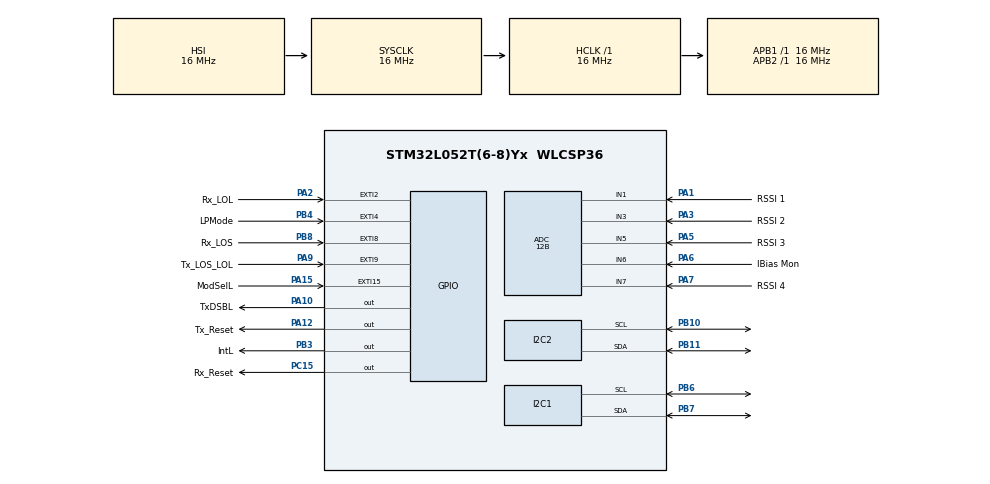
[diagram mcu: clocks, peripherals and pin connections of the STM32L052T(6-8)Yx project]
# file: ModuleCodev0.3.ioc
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ADC.ClockPrescaler=ADC_CLOCK_SYNC_PCLK_DIV1
ADC.ContinuousConvMode=DISABLE
ADC.DMAContinuousRequests=DISABLE
ADC.DataAlign=ADC_DATAALIGN_RIGHT
ADC.DiscontinuousConvMode=DISABLE
ADC.EOCSelection=ADC_EOC_SINGLE_CONV
ADC.EnableAnalogWatchDog=false
ADC.ExternalTrigConv=ADC_SOFTWARE_START
ADC.ExternalTrigConvEdge=ADC_EXTERNALTRIGCONVEDGE_NONE
ADC.LowPowerAutoPowerOff=DISABLE
ADC.LowPowerAutoWait=DISABLE
ADC.LowPowerFrequencyMode=DISABLE
ADC.Overrun=ADC_OVR_DATA_PRESERVED
ADC.OversamplingMode=DISABLE
ADC.Resolution=ADC_RESOLUTION_12B
ADC.SamplingTime=ADC_SAMPLETIME_1CYCLE_5
ADC.ScanConvMode=ADC_SCAN_DIRECTION_FORWARD
I2C1.OwnAddress=80
I2C1.Timing=0x00303D5B
I2C2.Timing=0x00303D5B
Mcu.Family=STM32L0
Mcu.Name=STM32L052T(6-8)Yx
Mcu.Package=WLCSP36
NVIC.ADC1_COMP_IRQn=true\:1\:0\:true\:false\:true
NVIC.EXTI2_3_IRQn=true\:2\:0\:true\:false\:true
NVIC.EXTI4_15_IRQn=true\:2\:0\:true\:false\:true
NVIC.I2C1_IRQn=true\:3\:0\:true\:false\:true
PA1.GPIO_Label=RSSI 1
PA1.Mode=IN1
PA1.Signal=ADC_IN1
PA10.GPIO_Label=TxDSBL
PA10.GPIO_ModeDefaultOutputPP=GPIO_MODE_OUTPUT_OD
PA10.GPIO_PuPd=GPIO_PULLUP
PA10.PinState=GPIO_PIN_RESET
PA10.Signal=GPIO_Output
PA12.GPIO_Label=Tx_Reset
PA12.GPIO_ModeDefaultOutputPP=GPIO_MODE_OUTPUT_OD
PA12.GPIO_PuPd=GPIO_PULLUP
PA12.PinState=GPIO_PIN_RESET
PA12.Signal=GPIO_Output
PA13.Mode=Serial_Wire
PA13.Signal=SYS_SWDIO
PA14.Mode=Serial_Wire
PA14.Signal=SYS_SWCLK
PA15.GPIO_Label=ModSelL
PA15.GPIO_ModeDefaultEXTI=GPIO_MODE_IT_RISING_FALLING
PA15.GPIO_PuPd=GPIO_PULLUP
PA15.Signal=GPXTI15
PA2.GPIO_Label=Rx_LOL
PA2.GPIO_ModeDefaultEXTI=GPIO_MODE_IT_RISING_FALLING
PA2.GPIO_PuPd=GPIO_PULLUP
PA2.Signal=GPXTI2
PA3.GPIO_Label=RSSI 2
PA3.Mode=IN3
PA3.Signal=ADC_IN3
PA5.GPIO_Label=RSSI 3
PA5.Mode=IN5
PA5.Signal=ADC_IN5
PA6.GPIO_Label=IBias Mon
PA6.Mode=IN6
PA6.Signal=ADC_IN6
PA7.GPIO_Label=RSSI 4
PA7.Mode=IN7
PA7.Signal=ADC_IN7
PA9.GPIO_Label=Tx_LOS_LOL
PA9.GPIO_ModeDefaultEXTI=GPIO_MODE_IT_RISING_FALLING
PA9.GPIO_PuPd=GPIO_PULLUP
PA9.Signal=GPXTI9
PB10.Mode=I2C
PB10.Signal=I2C2_SCL
PB11.Mode=I2C
PB11.Signal=I2C2_SDA
PB3.GPIO_Label=IntL
PB3.PinState=GPIO_PIN_SET
PB3.Signal=GPIO_Output
PB4.GPIO_Label=LPMode
PB4.GPIO_ModeDefaultEXTI=GPIO_MODE_IT_RISING_FALLING
PB4.GPIO_PuPd=GPIO_PULLUP
PB4.Signal=GPXTI4
PB6.Mode=I2C
PB6.Signal=I2C1_SCL
PB7.Mode=I2C
PB7.Signal=I2C1_SDA
PB8.GPIO_Label=Rx_LOS
PB8.GPIO_ModeDefaultEXTI=GPIO_MODE_IT_RISING_FALLING
PB8.GPIO_PuPd=GPIO_PULLUP
PB8.Signal=GPXTI8
PC15-OSC32_OUT.GPIO_Label=Rx_Reset
PC15-OSC32_OUT.GPIO_ModeDefaultOutputPP=GPIO_MODE_OUTPUT_OD
PC15-OSC32_OUT.GPIO_PuPd=GPIO_PULLUP
PC15-OSC32_OUT.PinState=GPIO_PIN_RESET
PC15-OSC32_OUT.Signal=GPIO_Output
ProjectManager.HeapSize=0x200
ProjectManager.StackSize=0x400
ProjectManager.TargetToolchain=MDK-ARM V5
RCC.AHBFreq_Value=16000000
RCC.APB1Freq_Value=16000000
RCC.APB1TimFreq_Value=16000000
RCC.APB2Freq_Value=16000000
RCC.APB2TimFreq_Value=16000000
RCC.HCLKFreq_Value=16000000
RCC.HSI16_VALUE=16000000
RCC.HSI48_VALUE=48000000
RCC.HSI_VALUE=16000000
RCC.LSE_VALUE=32768
RCC.MSI_VALUE=2097000
RCC.SYSCLKFreq_VALUE=16000000
RCC.SYSCLKSource=RCC_SYSCLKSOURCE_HSI
RCC.VCOOutputFreq_Value=48000000
VP_ADC_TempSens_Input.Mode=IN-TempSens
board=ModuleCodev0.3

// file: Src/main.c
/**
  ******************************************************************************
  * File Name          : main.c
  * Description        : Main program body
  ******************************************************************************
  ** This notice applies to any and all portions of this file
  * that are not between comment pairs USER CODE BEGIN and
  * USER CODE END. Other portions of this file, whether
  * inserted by the user or by software development tools
  * are owned by their respective copyright owners.
  *
  * COPYRIGHT(c) 2017 STMicroelectronics
  *
  * Redistribution and use in source and binary forms, with or without modification,
  * are permitted provided that the following conditions are met:
  *   1. Redistributions of source code must retain the above copyright notice,
  *      this list of conditions and the following disclaimer.
  *   2. Redistributions in binary form must reproduce the above copyright notice,
  *      this list of conditions and the following disclaimer in the documentation
  *      and/or other materials provided with the distribution.
  *   3. Neither the name of STMicroelectronics nor the names of its contributors
  *      may be used to endorse or promote products derived from this software
  *      without specific prior written permission.
  *
  * THIS SOFTWARE IS PROVIDED BY THE COPYRIGHT HOLDERS AND CONTRIBUTORS "AS IS"
  * AND ANY EXPRESS OR IMPLIED WARRANTIES, INCLUDING, BUT NOT LIMITED TO, THE
  * IMPLIED WARRANTIES OF MERCHANTABILITY AND FITNESS FOR A PARTICULAR PURPOSE ARE
  * DISCLAIMED. IN NO EVENT SHALL THE COPYRIGHT HOLDER OR CONTRIBUTORS BE LIABLE
  * FOR ANY DIRECT, INDIRECT, INCIDENTAL, SPECIAL, EXEMPLARY, OR CONSEQUENTIAL
  * DAMAGES (INCLUDING, BUT NOT LIMITED TO, PROCUREMENT OF SUBSTITUTE GOODS OR
  * SERVICES; LOSS OF USE, DATA, OR PROFITS; OR BUSINESS INTERRUPTION) HOWEVER
  * CAUSED AND ON ANY THEORY OF LIABILITY, WHETHER IN CONTRACT, STRICT LIABILITY,
  * OR TORT (INCLUDING NEGLIGENCE OR OTHERWISE) ARISING IN ANY WAY OUT OF THE USE
  * OF THIS SOFTWARE, EVEN IF ADVISED OF THE POSSIBILITY OF SUCH DAMAGE.
  *
  ******************************************************************************
  */
#include "main.h"
#include "stm32l0xx_hal.h"

/* USER CODE BEGIN Includes */
//将所有的需要模块执行的命令放入这主函数

#include "constant.h"
#include "Module_Slave_I2C.h"
#include "Module_MemMap.h"
#include "Module_Initialization.h"
#include "Module_Master_CDR.h"
#include "Module_MCU.h"
/* USER CODE END Includes */

ADC_HandleTypeDef hadc;

I2C_HandleTypeDef hi2c1;
I2C_HandleTypeDef hi2c2;

/* USER CODE BEGIN PV */
/* Private variables ---------------------------------------------------------*/

/* USER CODE END PV */

void SystemClock_Config(void);
static void MX_GPIO_Init(void);
static void MX_ADC_Init(void);
static void MX_I2C2_Init(void);
static void MX_I2C1_Init(void);

/* USER CODE BEGIN PFP */
/* Private function prototypes -----------------------------------------------*/

/* USER CODE END PFP */

int main(void)
{

  /* MCU Configuration----------------------------------------------------------*/

  /* Reset of all peripherals, Initializes the Flash interface and the Systick. */
  HAL_Init();

  /* Configure the system clock */
  SystemClock_Config();

  /* Initialize all configured peripherals */
  MX_GPIO_Init();
  MX_ADC_Init();
  MX_I2C2_Init();
  MX_I2C1_Init();

  /* USER CODE BEGIN 2 */
	Module_Init_Hardware();                                          //初始化版上硬件
	Module_Init_Register();                                          //初始化模块
	if(hi2c1.State == HAL_I2C_STATE_READY)                           //如果与上位机沟通的I2C空闲
	{
		I2C_Slave_Transreceiver_IT_Initialize(&hi2c1);                 //进入上位机I2C待命模式
	}
  /* USER CODE END 2 */

  /* Infinite loop */
  /* USER CODE BEGIN WHILE */
  while (1)
  {
		//HAL_PWR_EnterSLEEPMode(PWR_MAINREGULATOR_ON,PWR_SLEEPENTRY_WFI);    (进入中断唤醒的睡眠模式）
		//检查温度
		//检查提供电压                                 （可选）
		//检查调制电压                                 （可选）
		//检查各条路上的偏执和调制电流是否正常         （可选）
  /* USER CODE END WHILE */

  }

}

/** System Clock Configuration
*/
void SystemClock_Config(void)
{

  RCC_OscInitTypeDef RCC_OscInitStruct;
  RCC_ClkInitTypeDef RCC_ClkInitStruct;
  RCC_PeriphCLKInitTypeDef PeriphClkInit;

    /**Configure the main internal regulator output voltage
    */
  __HAL_PWR_VOLTAGESCALING_CONFIG(PWR_REGULATOR_VOLTAGE_SCALE1);

    /**Initializes the CPU, AHB and APB busses clocks
    */
  RCC_OscInitStruct.OscillatorType = RCC_OSCILLATORTYPE_HSI;
  RCC_OscInitStruct.HSIState = RCC_HSI_ON;
  RCC_OscInitStruct.HSICalibrationValue = 16;
  RCC_OscInitStruct.PLL.PLLState = RCC_PLL_NONE;
  if (HAL_RCC_OscConfig(&RCC_OscInitStruct) != HAL_OK)
  {
    _Error_Handler(__FILE__, __LINE__);
  }

    /**Initializes the CPU, AHB and APB busses clocks
    */
  RCC_ClkInitStruct.ClockType = RCC_CLOCKTYPE_HCLK|RCC_CLOCKTYPE_SYSCLK
                              |RCC_CLOCKTYPE_PCLK1|RCC_CLOCKTYPE_PCLK2;
  RCC_ClkInitStruct.SYSCLKSource = RCC_SYSCLKSOURCE_HSI;
  RCC_ClkInitStruct.AHBCLKDivider = RCC_SYSCLK_DIV1;
  RCC_ClkInitStruct.APB1CLKDivider = RCC_HCLK_DIV1;
  RCC_ClkInitStruct.APB2CLKDivider = RCC_HCLK_DIV1;

  if (HAL_RCC_ClockConfig(&RCC_ClkInitStruct, FLASH_LATENCY_0) != HAL_OK)
  {
    _Error_Handler(__FILE__, __LINE__);
  }

  PeriphClkInit.PeriphClockSelection = RCC_PERIPHCLK_I2C1;
  PeriphClkInit.I2c1ClockSelection = RCC_I2C1CLKSOURCE_PCLK1;
  if (HAL_RCCEx_PeriphCLKConfig(&PeriphClkInit) != HAL_OK)
  {
    _Error_Handler(__FILE__, __LINE__);
  }

    /**Configure the Systick interrupt time
    */
  HAL_SYSTICK_Config(HAL_RCC_GetHCLKFreq()/1000);

    /**Configure the Systick
    */
  HAL_SYSTICK_CLKSourceConfig(SYSTICK_CLKSOURCE_HCLK);

  /* SysTick_IRQn interrupt configuration */
  HAL_NVIC_SetPriority(SysTick_IRQn, 0, 0);
}

/* ADC init function */
static void MX_ADC_Init(void)
{

  ADC_ChannelConfTypeDef sConfig;

    /**Configure the global features of the ADC (Clock, Resolution, Data Alignment and number of conversion)
    */
  hadc.Instance = ADC1;
  hadc.Init.OversamplingMode = DISABLE;
  hadc.Init.ClockPrescaler = ADC_CLOCK_SYNC_PCLK_DIV1;
  hadc.Init.Resolution = ADC_RESOLUTION_12B;
  hadc.Init.SamplingTime = ADC_SAMPLETIME_1CYCLE_5;
  hadc.Init.ScanConvMode = ADC_SCAN_DIRECTION_FORWARD;
  hadc.Init.DataAlign = ADC_DATAALIGN_RIGHT;
  hadc.Init.ContinuousConvMode = DISABLE;
  hadc.Init.DiscontinuousConvMode = DISABLE;
  hadc.Init.ExternalTrigConvEdge = ADC_EXTERNALTRIGCONVEDGE_NONE;
  hadc.Init.ExternalTrigConv = ADC_SOFTWARE_START;
  hadc.Init.DMAContinuousRequests = DISABLE;
  hadc.Init.EOCSelection = ADC_EOC_SINGLE_CONV;
  hadc.Init.Overrun = ADC_OVR_DATA_PRESERVED;
  hadc.Init.LowPowerAutoWait = DISABLE;
  hadc.Init.LowPowerFrequencyMode = DISABLE;
  hadc.Init.LowPowerAutoPowerOff = DISABLE;
  if (HAL_ADC_Init(&hadc) != HAL_OK)
  {
    _Error_Handler(__FILE__, __LINE__);
  }

    /**Configure for the selected ADC regular channel to be converted.
    */
  sConfig.Channel = ADC_CHANNEL_1;
  sConfig.Rank = ADC_RANK_CHANNEL_NUMBER;
  if (HAL_ADC_ConfigChannel(&hadc, &sConfig) != HAL_OK)
  {
    _Error_Handler(__FILE__, __LINE__);
  }

    /**Configure for the selected ADC regular channel to be converted.
    */
  sConfig.Channel = ADC_CHANNEL_3;
  if (HAL_ADC_ConfigChannel(&hadc, &sConfig) != HAL_OK)
  {
    _Error_Handler(__FILE__, __LINE__);
  }

    /**Configure for the selected ADC regular channel to be converted.
    */
  sConfig.Channel = ADC_CHANNEL_5;
  if (HAL_ADC_ConfigChannel(&hadc, &sConfig) != HAL_OK)
  {
    _Error_Handler(__FILE__, __LINE__);
  }

    /**Configure for the selected ADC regular channel to be converted.
    */
  sConfig.Channel = ADC_CHANNEL_6;
  if (HAL_ADC_ConfigChannel(&hadc, &sConfig) != HAL_OK)
  {
    _Error_Handler(__FILE__, __LINE__);
  }

    /**Configure for the selected ADC regular channel to be converted.
    */
  sConfig.Channel = ADC_CHANNEL_7;
  if (HAL_ADC_ConfigChannel(&hadc, &sConfig) != HAL_OK)
  {
    _Error_Handler(__FILE__, __LINE__);
  }

    /**Configure for the selected ADC regular channel to be converted.
    */
  sConfig.Channel = ADC_CHANNEL_TEMPSENSOR;
  if (HAL_ADC_ConfigChannel(&hadc, &sConfig) != HAL_OK)
  {
    _Error_Handler(__FILE__, __LINE__);
  }

}

/* I2C1 init function */
static void MX_I2C1_Init(void)
{

  hi2c1.Instance = I2C1;
  hi2c1.Init.Timing = 0x00303D5B;
  hi2c1.Init.OwnAddress1 = 160;
  hi2c1.Init.AddressingMode = I2C_ADDRESSINGMODE_7BIT;
  hi2c1.Init.DualAddressMode = I2C_DUALADDRESS_DISABLE;
  hi2c1.Init.OwnAddress2 = 0;
  hi2c1.Init.OwnAddress2Masks = I2C_OA2_NOMASK;
  hi2c1.Init.GeneralCallMode = I2C_GENERALCALL_DISABLE;
  hi2c1.Init.NoStretchMode = I2C_NOSTRETCH_DISABLE;
  if (HAL_I2C_Init(&hi2c1) != HAL_OK)
  {
    _Error_Handler(__FILE__, __LINE__);
  }

    /**Configure Analogue filter
    */
  if (HAL_I2CEx_ConfigAnalogFilter(&hi2c1, I2C_ANALOGFILTER_ENABLE) != HAL_OK)
  {
    _Error_Handler(__FILE__, __LINE__);
  }

    /**Configure Digital filter
    */
  if (HAL_I2CEx_ConfigDigitalFilter(&hi2c1, 0) != HAL_OK)
  {
    _Error_Handler(__FILE__, __LINE__);
  }

}

/* I2C2 init function */
static void MX_I2C2_Init(void)
{

  hi2c2.Instance = I2C2;
  hi2c2.Init.Timing = 0x00303D5B;
  hi2c2.Init.OwnAddress1 = 0;
  hi2c2.Init.AddressingMode = I2C_ADDRESSINGMODE_7BIT;
  hi2c2.Init.DualAddressMode = I2C_DUALADDRESS_DISABLE;
  hi2c2.Init.OwnAddress2 = 0;
  hi2c2.Init.OwnAddress2Masks = I2C_OA2_NOMASK;
  hi2c2.Init.GeneralCallMode = I2C_GENERALCALL_DISABLE;
  hi2c2.Init.NoStretchMode = I2C_NOSTRETCH_DISABLE;
  if (HAL_I2C_Init(&hi2c2) != HAL_OK)
  {
    _Error_Handler(__FILE__, __LINE__);
  }

    /**Configure Analogue filter
    */
  if (HAL_I2CEx_ConfigAnalogFilter(&hi2c2, I2C_ANALOGFILTER_ENABLE) != HAL_OK)
  {
    _Error_Handler(__FILE__, __LINE__);
  }

    /**Configure Digital filter
    */
  if (HAL_I2CEx_ConfigDigitalFilter(&hi2c2, 0) != HAL_OK)
  {
    _Error_Handler(__FILE__, __LINE__);
  }

}

/** Configure pins as
        * Analog
        * Input
        * Output
        * EVENT_OUT
        * EXTI
*/
static void MX_GPIO_Init(void)
{

  GPIO_InitTypeDef GPIO_InitStruct;

  /* GPIO Ports Clock Enable */
  __HAL_RCC_GPIOA_CLK_ENABLE();
  __HAL_RCC_GPIOB_CLK_ENABLE();
  __HAL_RCC_GPIOC_CLK_ENABLE();

  /*Configure GPIO pin Output Level */
  HAL_GPIO_WritePin(GPIOA, Tx_Reset_Pin|TxDSBL_Pin, GPIO_PIN_RESET);

  /*Configure GPIO pin Output Level */
  HAL_GPIO_WritePin(IntL_GPIO_Port, IntL_Pin, GPIO_PIN_SET);

  /*Configure GPIO pin Output Level */
  HAL_GPIO_WritePin(Rx_Reset_GPIO_Port, Rx_Reset_Pin, GPIO_PIN_RESET);

  /*Configure GPIO pins : ModSelL_Pin Tx_LOS_LOL_Pin Rx_LOL_Pin */
  GPIO_InitStruct.Pin = ModSelL_Pin|Tx_LOS_LOL_Pin|Rx_LOL_Pin;
  GPIO_InitStruct.Mode = GPIO_MODE_IT_RISING_FALLING;
  GPIO_InitStruct.Pull = GPIO_PULLUP;
  HAL_GPIO_Init(GPIOA, &GPIO_InitStruct);

  /*Configure GPIO pins : LPMode_Pin Rx_LOS_Pin */
  GPIO_InitStruct.Pin = LPMode_Pin|Rx_LOS_Pin;
  GPIO_InitStruct.Mode = GPIO_MODE_IT_RISING_FALLING;
  GPIO_InitStruct.Pull = GPIO_PULLUP;
  HAL_GPIO_Init(GPIOB, &GPIO_InitStruct);

  /*Configure GPIO pins : Tx_Reset_Pin TxDSBL_Pin */
  GPIO_InitStruct.Pin = Tx_Reset_Pin|TxDSBL_Pin;
  GPIO_InitStruct.Mode = GPIO_MODE_OUTPUT_OD;
  GPIO_InitStruct.Pull = GPIO_PULLUP;
  GPIO_InitStruct.Speed = GPIO_SPEED_FREQ_LOW;
  HAL_GPIO_Init(GPIOA, &GPIO_InitStruct);

  /*Configure GPIO pin : IntL_Pin */
  GPIO_InitStruct.Pin = IntL_Pin;
  GPIO_InitStruct.Mode = GPIO_MODE_OUTPUT_PP;
  GPIO_InitStruct.Pull = GPIO_NOPULL;
  GPIO_InitStruct.Speed = GPIO_SPEED_FREQ_LOW;
  HAL_GPIO_Init(IntL_GPIO_Port, &GPIO_InitStruct);

  /*Configure GPIO pin : Rx_Reset_Pin */
  GPIO_InitStruct.Pin = Rx_Reset_Pin;
  GPIO_InitStruct.Mode = GPIO_MODE_OUTPUT_OD;
  GPIO_InitStruct.Pull = GPIO_PULLUP;
  GPIO_InitStruct.Speed = GPIO_SPEED_FREQ_LOW;
  HAL_GPIO_Init(Rx_Reset_GPIO_Port, &GPIO_InitStruct);

  /* EXTI interrupt init*/
  HAL_NVIC_SetPriority(EXTI2_3_IRQn, 2, 0);
  HAL_NVIC_EnableIRQ(EXTI2_3_IRQn);

  HAL_NVIC_SetPriority(EXTI4_15_IRQn, 2, 0);
  HAL_NVIC_EnableIRQ(EXTI4_15_IRQn);

}

void _Error_Handler(char * file, int line)
{
  while(1)
  {
  }
}

/************************ (C) COPYRIGHT STMicroelectronics *****END OF FILE****/
